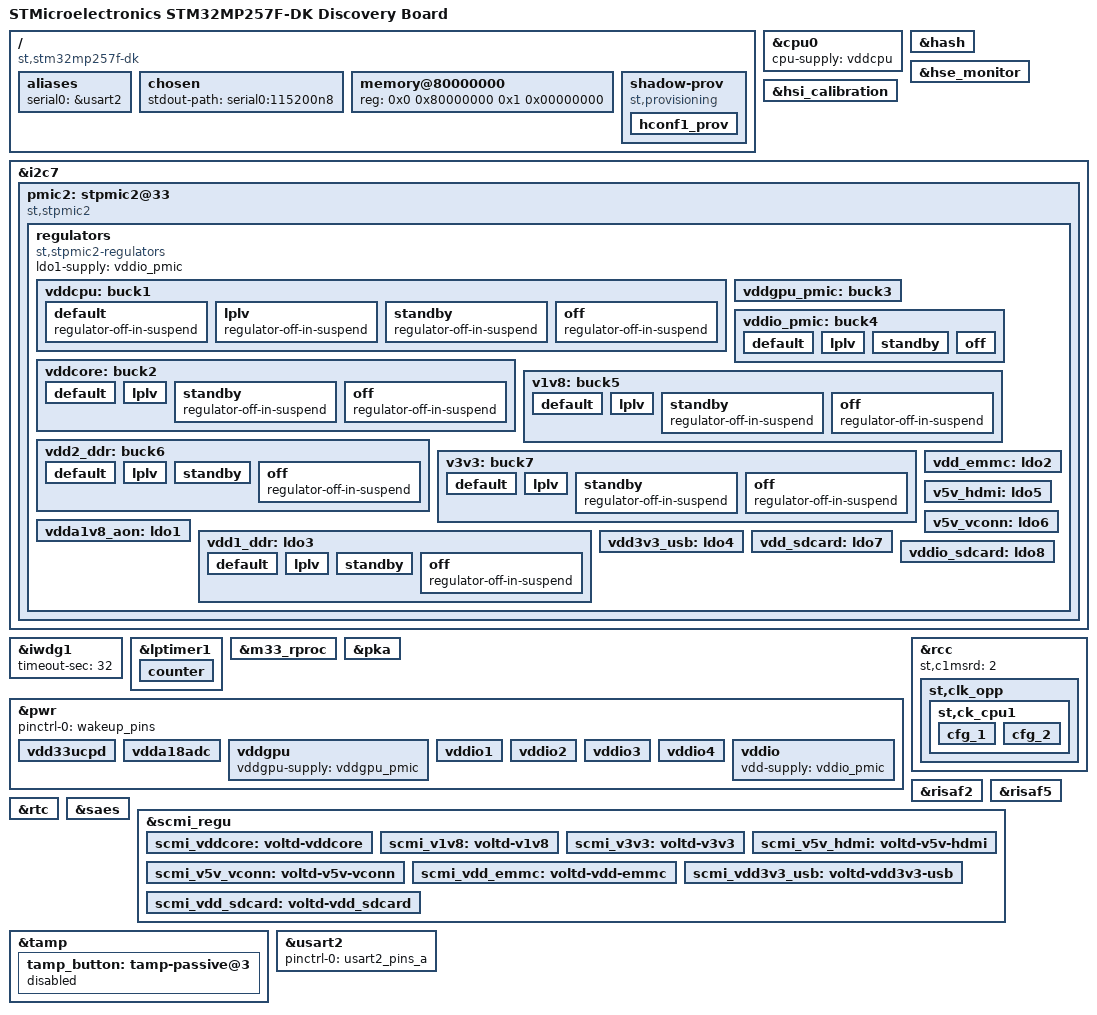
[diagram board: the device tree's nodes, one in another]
// SPDX-License-Identifier: (GPL-2.0-or-later OR BSD-3-Clause)
/*
 * Copyright (C) STMicroelectronics 2023 - All Rights Reserved
 * Author: Alexandre Torgue <alexandre.torgue@foss.st.com> for STMicroelectronics.
 */

/dts-v1/;

#include <dt-bindings/clock/stm32mp25-clksrc.h>
#include <dt-bindings/mfd/st,stpmic2.h>
#include <dt-bindings/regulator/st,stm32mp25-regulator.h>
#include <dt-bindings/reset/stm32mp25-resets.h>
#include <dt-bindings/soc/stm32mp-provisioning.h>
#include <dt-bindings/soc/stm32mp25-rif.h>
#include <dt-bindings/soc/stm32mp25-risab.h>
#include <dt-bindings/soc/stm32mp25-risaf.h>
#include <dt-bindings/soc/stm32mp25-rifsc.h>
#include <dt-bindings/tamper/st,stm32mp25-tamp.h>
#include "stm32mp257.dtsi"
#include "stm32mp25xf.dtsi"
#include "stm32mp257f-dk-ca35tdcid-rcc.dtsi"
#include "stm32mp257f-dk-ca35tdcid-resmem.dtsi"
#include "stm32mp257f-dk-ca35tdcid-rif.dtsi"
#include "stm32mp25-pinctrl.dtsi"
#include "stm32mp25xxal-pinctrl.dtsi"

/ {
	model = "STMicroelectronics STM32MP257F-DK Discovery Board";
	compatible = "st,stm32mp257f-dk", "st,stm32mp257";

	aliases {
		serial0 = &usart2;
	};

	chosen {
		stdout-path = "serial0:115200n8";
	};

	memory@80000000 {
		device_type = "memory";
		reg = <0x0 0x80000000 0x1 0x00000000>;
	};

	shadow-prov {
		compatible = "st,provisioning";
		hconf1_prov {
			nvmem-cells = <&hconf1_otp>;
			st,shadow-value = <0x00018DB6>;
		};
	};
};

&cpu0 {
	cpu-supply = <&vddcpu>;
};

&hash {
	status = "okay";
};

&hse_monitor {
	status = "okay";
};

&hsi_calibration {
	status = "okay";
};

&i2c7 {
	pinctrl-names = "default", "sleep";
	pinctrl-0 = <&i2c7_pins_a>;
	pinctrl-1 = <&i2c7_sleep_pins_a>;
	i2c-scl-rising-time-ns = <185>;
	i2c-scl-falling-time-ns = <20>;
	clock-frequency = <400000>;
	status = "okay";
	#address-cells = <1>;
	#size-cells = <0>;

	pmic2: stpmic2@33 {
		compatible = "st,stpmic2";
		reg = <0x33>;
		st,wakeup-pin-number = <1>;
		st,pmic-it-id = <IT_PKEY_FA IT_PKEY_RI>;
		st,notif-it-id = <0 1>;
		status = "okay";

		regulators {
			compatible = "st,stpmic2-regulators";

			ldo1-supply = <&vddio_pmic>;

			vddcpu: buck1 {
				regulator-name = "vddcpu";
				regulator-min-microvolt = <800000>;
				regulator-max-microvolt = <910000>;
				regulator-always-on;
				st,pwrctrl-sel = <2>;
				st,pwrctrl-enable;

				default {
					regulator-off-in-suspend;
				};
				lplv {
					regulator-off-in-suspend;
				};
				standby {
					regulator-off-in-suspend;
				};
				off {
					regulator-off-in-suspend;
				};
			};
			vddcore: buck2 {
				regulator-name = "vddcore";
				regulator-min-microvolt = <820000>;
				regulator-max-microvolt = <820000>;
				regulator-always-on;
				st,pwrctrl-sel = <1>;
				st,pwrctrl-enable;

				default {
					regulator-on-in-suspend;
					regulator-suspend-microvolt = <820000>;
				};
				lplv {
					regulator-on-in-suspend;
					regulator-suspend-microvolt = <670000>;
				};
				standby {
					regulator-off-in-suspend;
				};
				off {
					regulator-off-in-suspend;
				};
			};
			vddgpu_pmic: buck3 {
				regulator-name = "vddgpu_pmic";
				regulator-min-microvolt = <800000>;
				regulator-max-microvolt = <900000>;
				regulator-over-current-protection;
			};
			vddio_pmic: buck4 {
				regulator-name = "vddio_pmic";
				regulator-min-microvolt = <3300000>;
				regulator-max-microvolt = <3300000>;
				regulator-always-on;
				st,mask-reset;
				st,pwrctrl-sel = <1>;
				st,pwrctrl-enable;

				default {
					regulator-on-in-suspend;
					regulator-suspend-microvolt = <3300000>;
				};
				lplv {
					regulator-on-in-suspend;
					regulator-suspend-microvolt = <3300000>;
				};
				standby {
					regulator-on-in-suspend;
					regulator-suspend-microvolt = <3300000>;
				};
				off {
					/* ToDo: switch to LP */
					regulator-on-in-suspend;
					regulator-suspend-microvolt = <3300000>;
				};
			};
			v1v8: buck5 {
				regulator-name = "v1v8";
				regulator-min-microvolt = <1800000>;
				regulator-max-microvolt = <1800000>;
				regulator-always-on;
				st,pwrctrl-sel = <1>;
				st,pwrctrl-enable;

				default {
					regulator-on-in-suspend;
					regulator-suspend-microvolt = <1800000>;
				};
				lplv {
					regulator-on-in-suspend;
					regulator-suspend-microvolt = <1800000>;
				};
				standby {
					regulator-off-in-suspend;
				};
				off {
					regulator-off-in-suspend;
				};
			};
			vdd2_ddr: buck6 {
				regulator-name = "vdd2_ddr";
				regulator-min-microvolt = <1100000>;
				regulator-max-microvolt = <1100000>;
				regulator-always-on;
				st,pwrctrl-sel = <1>;
				st,pwrctrl-enable;

				default {
					regulator-on-in-suspend;
					regulator-suspend-microvolt = <1100000>;
				};
				lplv {
					regulator-on-in-suspend;
					regulator-suspend-microvolt = <1100000>;
				};
				standby {
					regulator-on-in-suspend;
					regulator-suspend-microvolt = <1100000>;
				};
				off {
					regulator-off-in-suspend;
				};
			};
			v3v3: buck7 {
				regulator-name = "v3v3";
				regulator-min-microvolt = <3300000>;
				regulator-max-microvolt = <3300000>;
				regulator-always-on;
				regulator-over-current-protection;
				st,pwrctrl-sel = <1>;
				st,pwrctrl-enable;

				default {
					regulator-on-in-suspend;
					regulator-suspend-microvolt = <3300000>;
				};
				lplv {
					regulator-on-in-suspend;
					regulator-suspend-microvolt = <3300000>;
				};
				standby {
					regulator-off-in-suspend;
				};
				off {
					regulator-off-in-suspend;
				};
			};
			vdda1v8_aon: ldo1 {
				regulator-name = "vdda1v8_aon";
				regulator-min-microvolt = <1800000>;
				regulator-max-microvolt = <1800000>;
				regulator-always-on;
				st,alternate-input-source;
				st,mask-reset;
			};
			vdd_emmc: ldo2 {
				regulator-name = "vdd_emmc";
				regulator-min-microvolt = <3300000>;
				regulator-max-microvolt = <3300000>;
				regulator-over-current-protection;
				st,pwrctrl-sel = <3>;
				st,pwrctrl-reset;
			};
			vdd1_ddr: ldo3 {
				regulator-name = "vdd1_ddr";
				regulator-min-microvolt = <1800000>;
				regulator-max-microvolt = <1800000>;
				regulator-always-on;
				st,pwrctrl-sel = <1>;
				st,pwrctrl-enable;

				default {
					regulator-on-in-suspend;
					regulator-suspend-microvolt = <1800000>;
				};
				lplv {
					regulator-on-in-suspend;
					regulator-suspend-microvolt = <1800000>;
				};
				standby {
					regulator-on-in-suspend;
					regulator-suspend-microvolt = <1800000>;
				};
				off {
					regulator-off-in-suspend;
				};
			};
			vdd3v3_usb: ldo4 {
				regulator-name = "vdd3v3_usb";
				regulator-min-microvolt = <3300000>;
				regulator-max-microvolt = <3300000>;
				regulator-always-on;
				regulator-over-current-protection;
			};
			v5v_hdmi: ldo5 {
				regulator-name = "v5v_hdmi";
				regulator-min-microvolt = <5000000>;
				regulator-max-microvolt = <5000000>;
				st,regulator-bypass-microvolt = <5000000>;
				st,pwrctrl-sel = <0>;
				st,pwrctrl-enable;
			};
			v5v_vconn: ldo6 {
				regulator-name = "v5v_vconn";
				regulator-min-microvolt = <5000000>;
				regulator-max-microvolt = <5000000>;
				regulator-always-on;
				st,regulator-bypass-microvolt = <5000000>;
				st,pwrctrl-sel = <0>;
				st,pwrctrl-reset;
			};
			vdd_sdcard: ldo7 {
				regulator-name = "vdd_sdcard";
				regulator-min-microvolt = <3300000>;
				regulator-max-microvolt = <3300000>;
				regulator-over-current-protection;
				st,regulator-bypass-microvolt = <3300000>;
				st,pwrctrl-sel = <3>;
				st,pwrctrl-reset;
			};
			vddio_sdcard: ldo8 {
				regulator-name = "vddio_sdcard";
				regulator-min-microvolt = <1800000>;
				regulator-max-microvolt = <3300000>;
				regulator-over-current-protection;
				st,regulator-bypass-microvolt = <3300000>;

				st,pwrctrl-sel = <3>;
				st,pwrctrl-reset;
			};
		};
	};
};

&iwdg1 {
	timeout-sec = <32>;
	status = "okay";
};

&lptimer1 {
	status = "okay";

	counter {
		status = "okay";
	};
};

&m33_rproc {
	status = "okay";
};

&pka {
	status = "okay";
};

&pwr {
	pinctrl-names = "default";
	pinctrl-0 = <&wakeup_pins>;
	status = "okay";

	vdd33ucpd: vdd33ucpd {
		status = "okay";
		regulator-min-microvolt = <3300000>;
		regulator-max-microvolt = <3300000>;
		vdd33ucpd-supply = <&vdd3v3_usb>;
		regulator-always-on;
	};

	vdda18adc: vdda18adc {
		status = "okay";
		regulator-min-microvolt = <1800000>;
		regulator-max-microvolt = <1800000>;
		vdda18adc-supply = <&v1v8>;
		regulator-always-on;
	};

	vddgpu: vddgpu {
		status = "okay";
		vddgpu-supply = <&vddgpu_pmic>;
	};

	vddio1: vddio1 {
		status = "okay";
		regulator-min-microvolt = <1800000>;
		regulator-max-microvolt = <3300000>;
		vddio1-supply = <&vddio_sdcard>;
	};

	vddio2: vddio2 {
		status = "okay";
		vddio2-supply = <&v1v8>;
		regulator-always-on;
	};

	vddio3: vddio3 {
		status = "okay";
		vddio3-supply = <&vddio_pmic>;
		regulator-always-on;
	};

	vddio4: vddio4 {
		status = "okay";
		vddio4-supply = <&vddio_pmic>;
		regulator-always-on;
	};

	vddio: vddio {
		status = "okay";
		vdd-supply = <&vddio_pmic>;
	};
};

&rcc {
	st,c1msrd = <2>;
	st,clk_opp {
		st,ck_cpu1 {
			cfg_1 {
				hz = <1500000000>;
				st,clksrc = <0>;
				st,pll = <&pll1_cfg_1500Mhz>;
			};

			cfg_2 {
				hz = <1200000000>;
				st,clksrc = <0>;
				st,pll = <&pll1_cfg_1200Mhz>;
			};
		};
	};
};

&risaf2 {
	status = "okay";
};

&risaf5 {
	status = "okay";
};

&rtc {
	status = "okay";
};

&saes {
	status = "okay";
};

&scmi_regu {
	scmi_vddcore: voltd-vddcore {
		reg = <VOLTD_SCMI_STPMIC2_BUCK2>;
		voltd-supply = <&vddcore>;
	};
	scmi_v1v8: voltd-v1v8 {
		reg = <VOLTD_SCMI_STPMIC2_BUCK5>;
		voltd-supply = <&v1v8>;
	};
	scmi_v3v3: voltd-v3v3 {
		reg = <VOLTD_SCMI_STPMIC2_BUCK7>;
		voltd-supply = <&v3v3>;
	};
	scmi_v5v_hdmi: voltd-v5v-hdmi {
		reg = <VOLTD_SCMI_STPMIC2_LDO5>;
		voltd-supply = <&v5v_hdmi>;
	};
	scmi_v5v_vconn: voltd-v5v-vconn {
		reg = <VOLTD_SCMI_STPMIC2_LDO6>;
		voltd-supply = <&v5v_vconn>;
	};
	scmi_vdd_emmc: voltd-vdd-emmc {
		reg = <VOLTD_SCMI_STPMIC2_LDO2>;
		voltd-supply = <&vdd_emmc>;
	};
	scmi_vdd3v3_usb: voltd-vdd3v3-usb {
		reg = <VOLTD_SCMI_STPMIC2_LDO4>;
		voltd-supply = <&vdd3v3_usb>;
	};
	scmi_vdd_sdcard: voltd-vdd_sdcard {
		reg = <VOLTD_SCMI_STPMIC2_LDO7>;
		voltd-supply = <&vdd_sdcard>;
	};
};

&tamp {
	wakeup-source;
	wakeup-parent = <&exti2>;
	st,tamp-passive-precharge = <2>;
	st,tamp-passive-nb-sample = <4>;
	st,tamp-passive-sample-clk-div = <16384>;

	/* Tamper button */
	tamp_button: tamp-passive@3 {
		status = "disabled";
		reg = <EXT_TAMPER_3 0>;
		pinctrl-0 = <&tamp_in3_pin_a>;
		st,tamp-mode = <TAMPER_POTENTIAL_MODE>;
	};
};

&usart2 {
	pinctrl-names = "default";
	pinctrl-0 = <&usart2_pins_a>;
	status = "okay";
};
